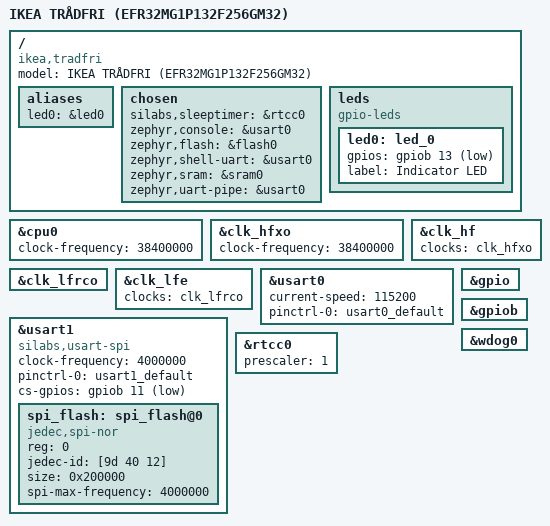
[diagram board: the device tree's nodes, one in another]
/*
 * Copyright The Zephyr Project Contributors
 *
 * SPDX-License-Identifier: Apache-2.0
 */

/dts-v1/;
#include <silabs/xg1/efr32mg1p132f256gm32.dtsi>
#include "ikea_tradfri-pinctrl.dtsi"

/ {
	model = "IKEA TRÅDFRI (EFR32MG1P132F256GM32)";
	compatible = "ikea,tradfri", "silabs,efr32mg1p";

	aliases {
		led0 = &led0;
	};

	chosen {
		/* RTCC is also the low power clock source, so the system
		 * tick keeps running while the CPU is in EM1 or EM2.
		 */
		silabs,sleeptimer = &rtcc0;
		zephyr,console = &usart0;
		zephyr,flash = &flash0;
		zephyr,shell-uart = &usart0;
		zephyr,sram = &sram0;
		zephyr,uart-pipe = &usart0;
	};

	leds {
		compatible = "gpio-leds";

		led0: led_0 {
			gpios = <&gpiob 13 GPIO_ACTIVE_LOW>;
			label = "Indicator LED";
		};
	};
};

&cpu0 {
	clock-frequency = <38400000>;
};

&clk_hfxo {
	clock-frequency = <38400000>;
	status = "okay";
};

&clk_hf {
	clocks = <&clk_hfxo>;
};

&clk_lfrco {
	status = "okay";
};

&clk_lfe {
	clocks = <&clk_lfrco>;
	status = "okay";
};

&usart0 {
	current-speed = <115200>;
	pinctrl-0 = <&usart0_default>;
	pinctrl-names = "default";
	status = "okay";
};

/* USART1 in SPI master mode drives the on-board 256 kB SPI NOR flash. */
&usart1 {
	compatible = "silabs,usart-spi";
	clock-frequency = <4000000>;
	#address-cells = <1>;
	#size-cells = <0>;
	pinctrl-0 = <&usart1_default>;
	pinctrl-names = "default";
	cs-gpios = <&gpiob 11 GPIO_ACTIVE_LOW>;
	status = "okay";

	spi_flash: spi_flash@0 {
		compatible = "jedec,spi-nor";
		reg = <0>;
		jedec-id = [9d 40 12];
		size = <0x200000>; /* 2 Mbit */
		spi-max-frequency = <4000000>;
	};
};

&rtcc0 {
	prescaler = <1>;
	status = "okay";
};

&gpio {
	status = "okay";
};

&gpiob {
	status = "okay";
};

&wdog0 {
	status = "okay";
};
